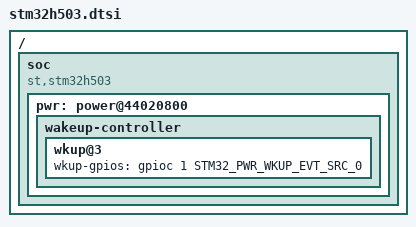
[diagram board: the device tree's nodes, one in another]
/*
 * Copyright (c) 2023 STMicroelectronics
 *
 * SPDX-License-Identifier: Apache-2.0
 */

#include <st/h5/stm32h5.dtsi>

/ {
	soc {
		compatible = "st,stm32h503", "st,stm32h5", "simple-bus";

		pwr: power@44020800 {
			wakeup-controller {
				wkup@3 {
					wkup-gpios = <&gpioc 1 STM32_PWR_WKUP_EVT_SRC_0>;
				};
			};
		};
	};
};
